# Star_MC1 register map
Vendor: Arm Ltd.; Series: ARMv8-M Mainline; File version: 1.0.0
CPU: other r0p0, little endian, MPU, FPU, double-precision FPU, DSP, 8 interrupt priority bits
Registers are 32-bit, read-write, reset 0x0 unless marked. A register's access mark holds for its fields unless they carry their own. Offsets are from the block's base; [hi:lo] are bit positions.

## SAU — Security Attribution Unit (ARMv8-M Security Extension): defines which address ranges are Non-secure or Secure Non-secure-callable; everything else is Secure. Also holds the SecureFault status and address registers.
Base 0xE000EDD0
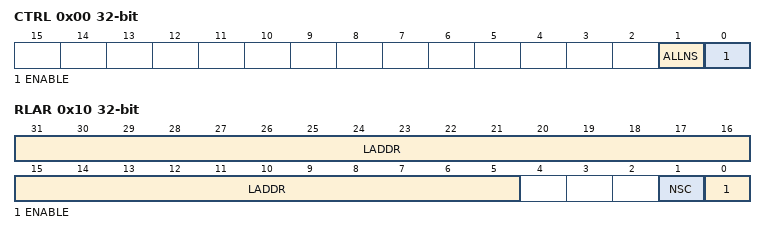
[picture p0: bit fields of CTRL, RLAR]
0x00 CTRL — SAU Control Register: enable, and what the memory map looks like while the SAU is disabled.
  [1] ALLNS — All Non-secure: with the SAU disabled, 1 = memory not marked Secure by the IDAU is Non-secure, 0 = all memory is Secure.
  [0] ENABLE — SAU enable. When 0 the whole address space is Secure (ALLNS = 0) or Non-secure (ALLNS = 1), subject to the IDAU.
0x04 TYPE ro — SAU Type Register: number of SAU regions implemented (0, 4 or 8 on Arm cores). Read-only.
  [7:0] SREGION — Number of SAU regions implemented (0, 4 or 8).
0x08 RNR — SAU Region Number Register: selects the region that RBAR and RLAR access.
  [7:0] REGION — Region selected for RBAR/RLAR accesses.
0x0C RBAR — SAU Region Base Address Register: start address (32-byte aligned) of the selected region.
  [31:5] BADDR — Region start address bits [31:5] (32-byte granularity).
0x10 RLAR — SAU Region Limit Address Register: inclusive end address, Non-secure-callable attribute and enable of the selected region.
  [31:5] LADDR — Region end address bits [31:5]; the low five bits are treated as 1 (inclusive limit).
  [1] NSC — 1 = the region is Secure and Non-secure-callable (holds the SG entry veneers); 0 = the region is Non-secure.
  [0] ENABLE — Region enable.

## DIB — Debug Identification Block (ARMv8-M): software lock, debug authentication status and the SCS CoreSight architecture and type IDs.
Base 0xE000EFB0
Same registers: DIB_NS 0xE002EFB0
0x00 DLAR wo — SCS Software Lock Access Register: write 0xC5ACCE55 to unlock software writes to the SCS debug registers when the software lock is implemented (DLSR.SLI).
  [31:0] KEY — Write 0xC5ACCE55 to unlock software access to the SCS debug registers; any other value locks them.
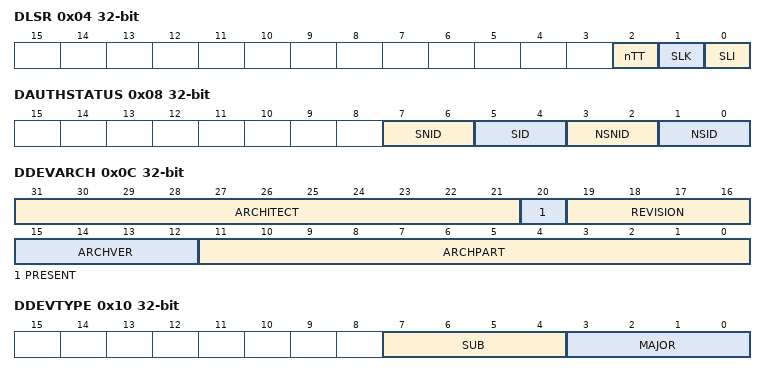
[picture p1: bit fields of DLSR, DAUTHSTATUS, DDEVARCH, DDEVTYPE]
0x04 DLSR ro — SCS Software Lock Status Register: whether a software lock exists and whether it is currently locked.
  [2] nTT — Not thirty-two bit: 0 = DLAR is a 32-bit register.
  [1] SLK — Software lock status: 1 = locked (software writes to the debug registers are ignored; the debugger is never locked).
  [0] SLI — Software lock implemented.
0x08 DAUTHSTATUS ro — Debug Authentication Status Register: which kinds of debug (invasive/non-invasive, Secure/Non-secure, unprivileged) are currently enabled.
  [7:6] SNID — Secure non-invasive debug: 0 = not implemented, 2 = disabled, 3 = enabled.
  [5:4] SID — Secure invasive debug: 0 = not implemented, 2 = disabled, 3 = enabled.
  [3:2] NSNID — Non-secure non-invasive debug (trace): 0 = not implemented, 2 = disabled, 3 = enabled.
  [1:0] NSID — Non-secure invasive debug: 0 = not implemented, 2 = disabled, 3 = enabled.
0x0C DDEVARCH ro — SCS Device Architecture Register: CoreSight ARCHID of the debug architecture (0x2A04 = ARMv8-M debug) and the architect (Arm, 0x23B).
  [31:21] ARCHITECT — JEP106 code of the architect: 0x23B = Arm.
  [20] PRESENT — 1 = DDEVARCH is present and its contents are valid.
  [19:16] REVISION — Architecture revision.
  [15:12] ARCHVER — Architecture version: 2 = ARMv8-M debug architecture.
  [11:0] ARCHPART — Architecture part: 0xA04 = M-profile system control space (with ARCHVER 2 -> ARCHID 0x2A04, ARMv8-M debug).
0x10 DDEVTYPE ro — SCS Device Type Register: CoreSight major/sub type of the SCS (0x00 = processor system control).
  [7:4] SUB — Sub type: 0 for the SCS.
  [3:0] MAJOR — Major type: 0 = miscellaneous / processor system control.

## EMSS — Embedded Memory Subsystem control (STAR-MC1): L1 cache control and the ITCM/DTCM enables and sizes.
Base 0xE001E000
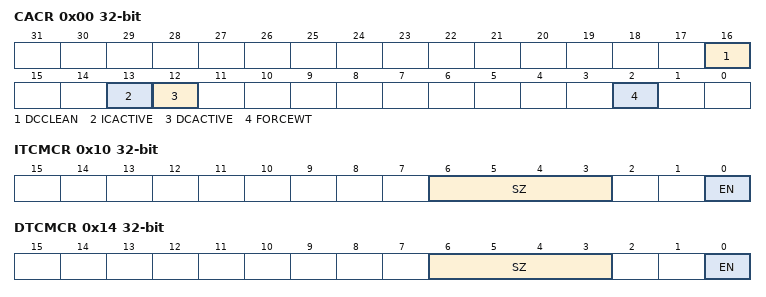
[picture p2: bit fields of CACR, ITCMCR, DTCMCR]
0x00 CACR — L1 Cache Control Register (STAR-MC1): forced write-through and cache status.
  [16] DCCLEAN — Data cache clean (read-only): 1 = no dirty lines.
  [13] ICACTIVE — Instruction cache active (read-only).
  [12] DCACTIVE — Data cache active (read-only).
  [2] FORCEWT — Force write-through: 1 = all cacheable data is cached write-through.
0x10 ITCMCR — ITCM Control Register (STAR-MC1): enable and size of the instruction TCM.
  [6:3] SZ — TCM size: 0 = none, 3 = 4 KB, 4 = 8 KB, 5 = 16 KB, 6 = 32 KB, 7 = 64 KB, 8 = 128 KB, 9 = 256 KB, 10 = 512 KB, 11 = 1 MB, 12 = 2 MB, 13 = 4 MB, 14 = 8 MB, 15 = 16 MB (2^(SZ-1) KB). Read-only.
  [0] EN — ITCM enable.
0x14 DTCMCR — DTCM Control Register (STAR-MC1): enable and size of the data TCM.
  [6:3] SZ — TCM size: 0 = none, 3 = 4 KB, 4 = 8 KB, 5 = 16 KB, 6 = 32 KB, 7 = 64 KB, 8 = 128 KB, 9 = 256 KB, 10 = 512 KB, 11 = 1 MB, 12 = 2 MB, 13 = 4 MB, 14 = 8 MB, 15 = 16 MB (2^(SZ-1) KB). Read-only.
  [0] EN — DTCM enable.
